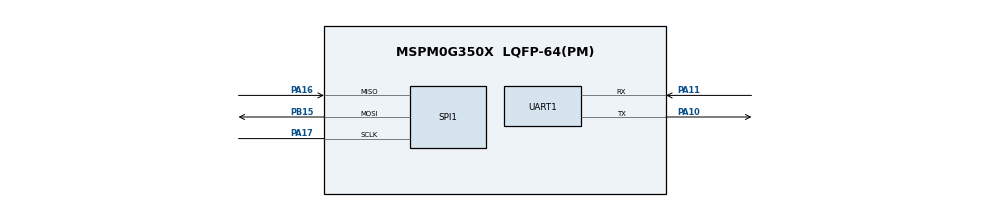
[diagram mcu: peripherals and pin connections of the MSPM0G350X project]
/**
 * @cliArgs --device "MSPM0G350X" --part "Default" --package "LQFP-64(PM)" --product "mspm0_sdk@2.10.00.04"
 * @versions {"tool":"1.26.2+4477"}
 */

/**
 * Import the modules used in this configuration.
 */
const GPIO   = scripting.addModule("/ti/driverlib/GPIO", {}, false);
const GPIO1  = GPIO.addInstance();
const SPI    = scripting.addModule("/ti/driverlib/SPI", {}, false);
const SPI1   = SPI.addInstance();
const SYSCTL = scripting.addModule("/ti/driverlib/SYSCTL");
const UART   = scripting.addModule("/ti/driverlib/UART", {}, false);
const UART1  = UART.addInstance();

/**
 * Write custom configuration values to the imported modules.
 */
GPIO1.$name                          = "GPIO_CS";
GPIO1.associatedPins[0].$name        = "CS_PIN";
GPIO1.associatedPins[0].assignedPort = "PORTA";
GPIO1.associatedPins[0].assignedPin  = "27";
GPIO1.associatedPins[0].initialValue = "SET";

const Board = scripting.addModule("/ti/driverlib/Board", {}, false);

// Configure SPI1 as Master (Controller) at 2MHz, Mode 0 (CPOL=0, CPHA=0)
SPI1.$name                              = "SPI_G356";
SPI1.mode                               = "CONTROLLER";
SPI1.targetBitRate                      = 2000000;
SPI1.frameFormat                        = "MOTO3";
SPI1.sclkPinConfig.$name                = "ti_driverlib_gpio_GPIOPinGeneric0";
SPI1.sclkPinConfig.direction            = scripting.forceWrite("OUTPUT");
SPI1.sclkPinConfig.onlyInternalResistor = scripting.forceWrite(false);
SPI1.sclkPinConfig.passedPeripheralType = scripting.forceWrite("Digital");
SPI1.mosiPinConfig.$name                = "ti_driverlib_gpio_GPIOPinGeneric1";
SPI1.mosiPinConfig.direction            = scripting.forceWrite("OUTPUT");
SPI1.mosiPinConfig.hideOutputInversion  = scripting.forceWrite(false);
SPI1.mosiPinConfig.onlyInternalResistor = scripting.forceWrite(false);
SPI1.mosiPinConfig.passedPeripheralType = scripting.forceWrite("Digital");
SPI1.misoPinConfig.$name                = "ti_driverlib_gpio_GPIOPinGeneric2";
SPI1.misoPinConfig.onlyInternalResistor = scripting.forceWrite(false);
SPI1.misoPinConfig.passedPeripheralType = scripting.forceWrite("Digital");
SPI1.peripheral.$assign                 = "SPI1";
SPI1.peripheral.sclkPin.$assign         = "PA17";
SPI1.peripheral.mosiPin.$assign         = "PB15";
SPI1.peripheral.misoPin.$assign         = "PA16";

SYSCTL.forceDefaultClkConfig = true;

UART1.$name                            = "UART_DEBUG";
UART1.targetBaudRate                   = 115200;
UART1.peripheral.$assign               = "UART0";
UART1.peripheral.rxPin.$assign         = "PA11";
UART1.peripheral.txPin.$assign         = "PA10";
UART1.txPinConfig.direction            = scripting.forceWrite("OUTPUT");
UART1.txPinConfig.hideOutputInversion  = scripting.forceWrite(false);
UART1.txPinConfig.onlyInternalResistor = scripting.forceWrite(false);
UART1.txPinConfig.passedPeripheralType = scripting.forceWrite("Digital");
UART1.txPinConfig.$name                = "ti_driverlib_gpio_GPIOPinGeneric3";
UART1.rxPinConfig.hideOutputInversion  = scripting.forceWrite(false);
UART1.rxPinConfig.onlyInternalResistor = scripting.forceWrite(false);
UART1.rxPinConfig.passedPeripheralType = scripting.forceWrite("Digital");
UART1.rxPinConfig.$name                = "ti_driverlib_gpio_GPIOPinGeneric4";

const ProjectConfig              = scripting.addModule("/ti/project_config/ProjectConfig", {}, false);
ProjectConfig.migrationCondition = true;

/**
 * Pinmux solution for unlocked pins/peripherals. This ensures that minor changes to the automatic solver in a future
 * version of the tool will not impact the pinmux you originally saw.  These lines can be completely deleted in order to
 * re-solve from scratch.
 */
GPIO1.associatedPins[0].pin.$suggestSolution = "PA27";
Board.peripheral.$suggestSolution            = "DEBUGSS";
Board.peripheral.swclkPin.$suggestSolution   = "PA20";
Board.peripheral.swdioPin.$suggestSolution   = "PA19";
SYSCTL.peripheral.$suggestSolution           = "SYSCTL";
